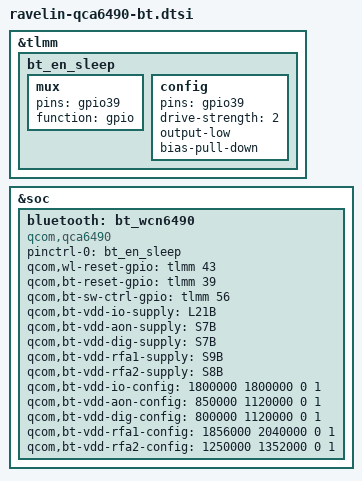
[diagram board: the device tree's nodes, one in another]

/*Copyright (c) Qualcomm Technologies, Inc. and/or its subsidiaries.
 *SPDX-License-Identifier: BSD-3-Clause
 */

#include <dt-bindings/interconnect/qcom,ravelin.h>
#include <dt-bindings/clock/qcom,rpmh.h>

&tlmm {
bt_en_sleep: bt_en_sleep {
mux {
 pins = "gpio39";
 function = "gpio";
};
config {
pins = "gpio39";
drive-strength = <2>;
output-low;
bias-pull-down;
};
};
};

&soc {
	bluetooth: bt_wcn6490 {
		status =  "ok";
		compatible = "qcom,qca6490";
		pinctrl-names = "default";
		pinctrl-0 = <&bt_en_sleep>;
		qcom,wl-reset-gpio = <&tlmm 43 0>; /* WL_CTRL */
		qcom,bt-reset-gpio = <&tlmm 39 0>; /* BT_EN */
		qcom,bt-sw-ctrl-gpio = <&tlmm 56 0>; /* SW_CTRL */

		qcom,bt-vdd-io-supply = <&L21B>;  /* IO */
		qcom,bt-vdd-aon-supply = <&S7B>;
		qcom,bt-vdd-dig-supply = <&S7B>; /* BT_CX_MX */
		qcom,bt-vdd-rfa1-supply = <&S9B>; /* RFA 1p7 */
		qcom,bt-vdd-rfa2-supply = <&S8B>; /* RFA 1p2 */

		/* Max Voltages are derived from the buck Max Voltage */
		qcom,bt-vdd-io-config = <1800000 1800000 0 1>;
		qcom,bt-vdd-aon-config = <850000 1120000 0 1>;
		qcom,bt-vdd-dig-config = <800000 1120000 0 1>;
		qcom,bt-vdd-rfa1-config = <1856000 2040000 0 1>;
		qcom,bt-vdd-rfa2-config = <1250000 1352000 0 1>;
	};

};


